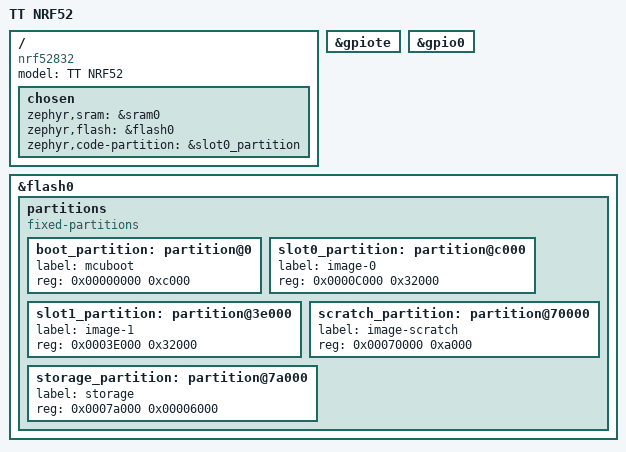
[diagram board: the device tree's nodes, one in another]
/*
 * Copyright (c) 2019 Henrik Brix Andersen <henrik@brixandersen.dk>
 *
 * SPDX-License-Identifier: Apache-2.0
 */

/dts-v1/;
#include <nordic/nrf52832_qfaa.dtsi>

/ {
	model = "TT NRF52";
	compatible = "nrf52832";

	chosen {
		zephyr,sram = &sram0;
		zephyr,flash = &flash0;
		zephyr,code-partition = &slot0_partition;
	};
};

&gpiote {
	status = "okay";
};

&gpio0 {
	status = "okay";
};

&flash0 {

	partitions {
		compatible = "fixed-partitions";
		#address-cells = <1>;
		#size-cells = <1>;

		boot_partition: partition@0 {
			label = "mcuboot";
			reg = <0x00000000 0xc000>;
		};
		slot0_partition: partition@c000 {
			label = "image-0";
			reg = <0x0000C000 0x32000>;
		};
		slot1_partition: partition@3e000 {
			label = "image-1";
			reg = <0x0003E000 0x32000>;
		};
		scratch_partition: partition@70000 {
			label = "image-scratch";
			reg = <0x00070000 0xa000>;
		};
		storage_partition: partition@7a000 {
			label = "storage";
			reg = <0x0007a000 0x00006000>;
		};
	};
};
